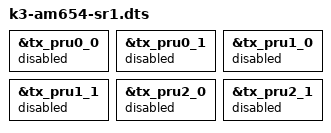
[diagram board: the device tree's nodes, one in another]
// SPDX-License-Identifier: GPL-2.0
/*
 * DT overlay for AM65x SR1.0 Silicon
 *
 * Copyright (C) 2021 Texas Instruments Incorporated - https://www.ti.com/
 */

/dts-v1/;
/plugin/;

&tx_pru0_0 {
	status = "disabled";
};

&tx_pru0_1 {
	status = "disabled";
};

&tx_pru1_0 {
	status = "disabled";
};

&tx_pru1_1 {
	status = "disabled";
};

&tx_pru2_0 {
	status = "disabled";
};

&tx_pru2_1 {
	status = "disabled";
};
